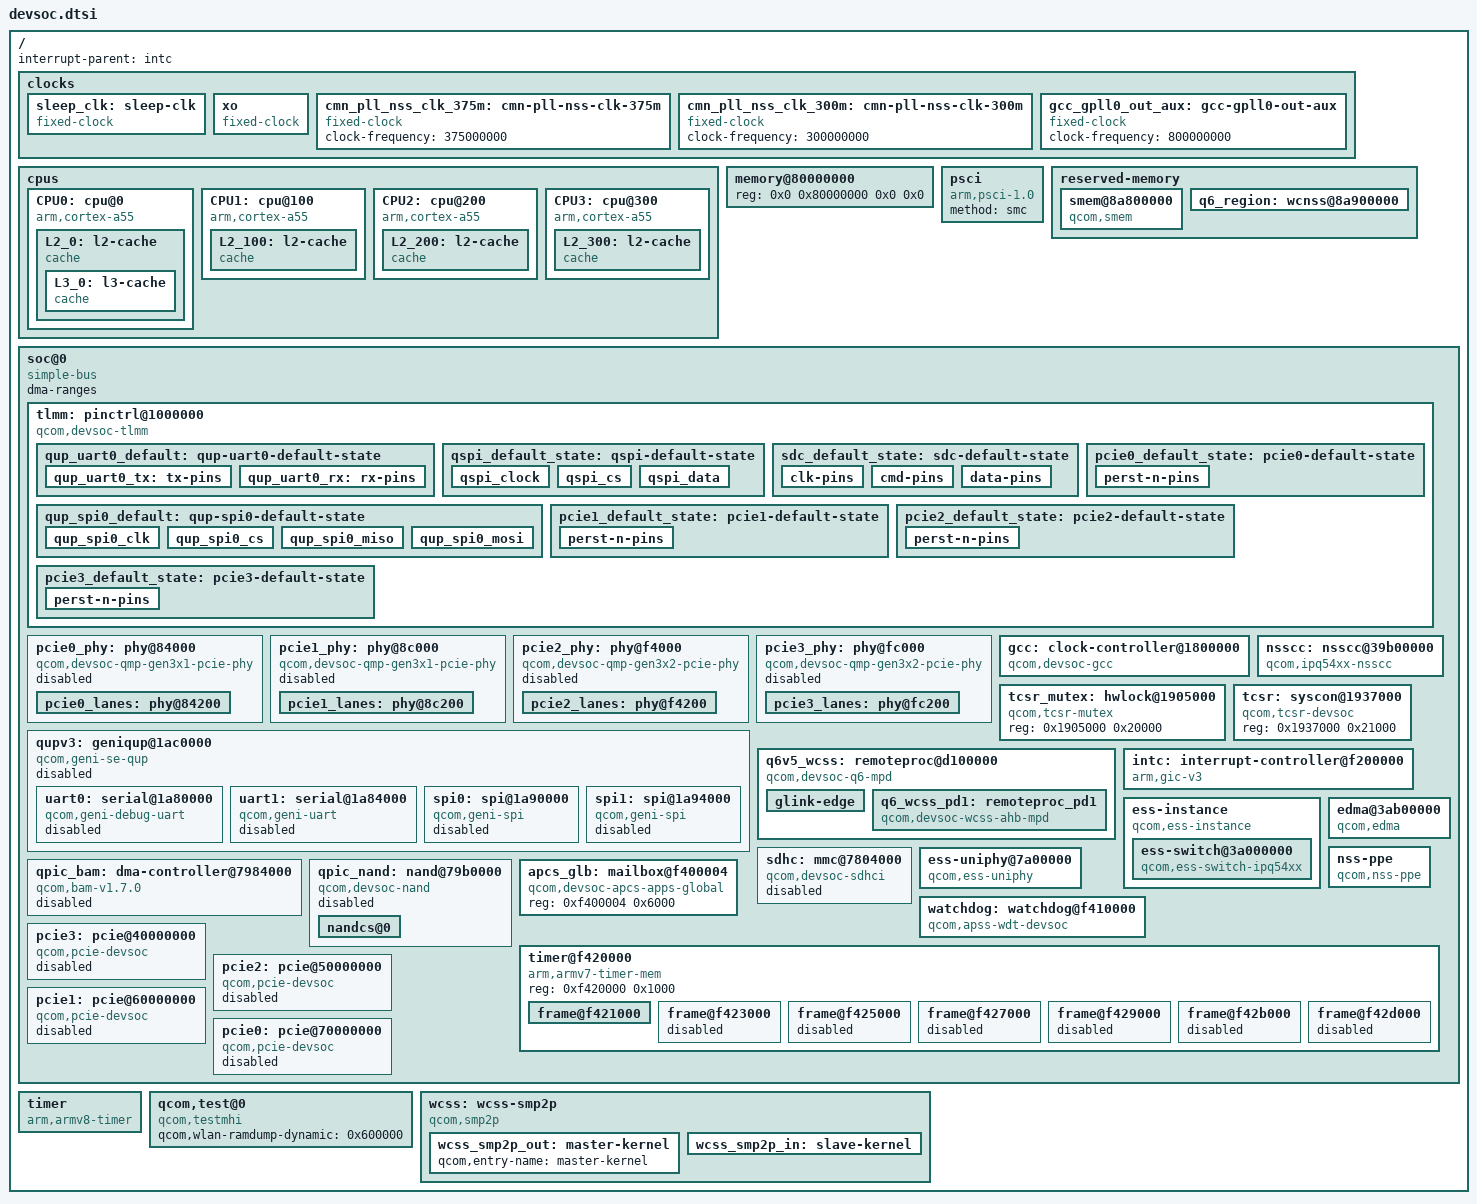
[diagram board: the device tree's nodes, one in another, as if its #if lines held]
// SPDX-License-Identifier: (GPL-2.0+ OR BSD-3-Clause)
/*
 * Dev SoC device tree source
 *
 * Copyright (c) 2020-2021 The Linux Foundation. All rights reserved.
 * Copyright (c) 2022-2023 Qualcomm Innovation Center, Inc. All rights reserved.
 */

#include <dt-bindings/interrupt-controller/arm-gic.h>
#include <dt-bindings/clock/qcom,devsoc-gcc.h>
#include <dt-bindings/reset/qcom,devsoc-gcc.h>
#include <dt-bindings/gpio/gpio.h>
#include <dt-bindings/clock/qcom,devsoc-nsscc.h>
#include <dt-bindings/reset/qcom,devsoc-nsscc.h>

/ {
	#address-cells = <2>;
	#size-cells = <2>;
	interrupt-parent = <&intc>;

	clocks {
		sleep_clk: sleep-clk {
			compatible = "fixed-clock";
			#clock-cells = <0>;
		};

		xo: xo {
			compatible = "fixed-clock";
			#clock-cells = <0>;
		};

		cmn_pll_nss_clk_375m: cmn-pll-nss-clk-375m {
			compatible = "fixed-clock";
			clock-frequency = <375000000>;
			#clock-cells = <0>;
		};

		cmn_pll_nss_clk_300m: cmn-pll-nss-clk-300m {
			compatible = "fixed-clock";
			clock-frequency = <300000000>;
			#clock-cells = <0>;
		};

		gcc_gpll0_out_aux: gcc-gpll0-out-aux {
			compatible = "fixed-clock";
			clock-frequency = <800000000>;
			#clock-cells = <0>;
		};
	};

	cpus: cpus {
		#address-cells = <1>;
		#size-cells = <0>;

		CPU0: cpu@0 {
			device_type = "cpu";
			compatible = "arm,cortex-a55";
			reg = <0x0>;
			enable-method = "psci";
			next-level-cache = <&L2_0>;
			L2_0: l2-cache {
				compatible = "cache";
				cache-level = <2>;
				cache-unified;
				next-level-cache = <&L3_0>;
				L3_0: l3-cache {
					compatible = "cache";
					cache-level = <3>;
					cache-unified;
				};
			};
		};

		CPU1: cpu@100 {
			device_type = "cpu";
			compatible = "arm,cortex-a55";
			enable-method = "psci";
			reg = <0x100>;
			next-level-cache = <&L2_100>;
			L2_100: l2-cache {
				compatible = "cache";
				cache-level = <2>;
				cache-unified;
				next-level-cache = <&L3_0>;
			};
		};

		CPU2: cpu@200 {
			device_type = "cpu";
			compatible = "arm,cortex-a55";
			enable-method = "psci";
			reg = <0x200>;
			next-level-cache = <&L2_200>;
			L2_200: l2-cache {
				compatible = "cache";
				cache-level = <2>;
				cache-unified;
				next-level-cache = <&L3_0>;
			};
		};

		CPU3: cpu@300 {
			device_type = "cpu";
			compatible = "arm,cortex-a55";
			enable-method = "psci";
			reg = <0x300>;
			next-level-cache = <&L2_300>;
			L2_300: l2-cache {
				compatible = "cache";
				cache-level = <2>;
				cache-unified;
				next-level-cache = <&L3_0>;
			};
		};
	};

	memory@80000000 {
		device_type = "memory";
		/* We expect the bootloader to fill in the size */
		reg = <0x0 0x80000000 0x0 0x0>;
	};

	psci {
		compatible = "arm,psci-1.0";
		method = "smc";
	};

	reserved-memory {
		#address-cells = <2>;
		#size-cells = <2>;
		ranges;

		smem@8a800000 {
			compatible = "qcom,smem";
			reg = <0x0 0x8a800000 0x0 0x100000>;
			no-map;

			hwlocks = <&tcsr_mutex 3>;
		};

		q6_region: wcnss@8a900000 {
			reg = <0x0 0x8a900000 0x0 0x02300000>;
			no-map;
		};
	};

	soc@0 {
		compatible = "simple-bus";
		#address-cells = <1>;
		#size-cells = <1>;
		ranges = <0 0 0 0xffffffff>;
		dma-ranges;

		tlmm: pinctrl@1000000 {
			compatible = "qcom,devsoc-tlmm";
			reg = <0x01000000 0x300000>;
			interrupts = <GIC_SPI 84 IRQ_TYPE_LEVEL_HIGH>;
			gpio-controller;
			#gpio-cells = <2>;
			gpio-ranges = <&tlmm 0 0 49>;
			interrupt-controller;
			#interrupt-cells = <2>;

			qup_uart0_default: qup-uart0-default-state {
				qup_uart0_tx: tx-pins {
					pins = "gpio13";
					function = "uart0_tx";
					drive-strength = <8>;
					bias-disable;
				};

				qup_uart0_rx: rx-pins {
					pins = "gpio12";
					function = "uart0_rx";
					drive-strength = <8>;
					bias-disable;
				};
			};

			qspi_default_state: qspi-default-state {
				qspi_clock {
					pins = "gpio5";
					function = "qspi_clk";
					drive-strength = <8>;
					bias-pull-down;
				};

				qspi_cs {
					pins = "gpio4";
					function = "qspi_cs";
					drive-strength = <8>;
					bias-pull-up;
				};

				qspi_data {
					pins = "gpio0", "gpio1", "gpio2", "gpio3";
					function = "qspi_data";
					drive-strength = <8>;
					bias-pull-down;
				};
			};

			sdc_default_state: sdc-default-state {
				clk-pins {
					pins = "gpio5";
					function = "sdc_clk";
					drive-strength = <8>;
					bias-disable;
				};

				cmd-pins {
					pins = "gpio4";
					function = "sdc_cmd";
					drive-strength = <8>;
					bias-pull-up;
				};

				data-pins {
					pins = "gpio0", "gpio1", "gpio2", "gpio3";
					function = "sdc_data";
					drive-strength = <8>;
					bias-pull-up;
				};
			};

			qup_spi0_default: qup-spi0-default-state {
				qup_spi0_clk {
					pins = "gpio6";
					function = "spi0_clk";
					drive-strength = <8>;
					bias-disable;
				};

				qup_spi0_cs {
					pins = "gpio7";
					function = "spi0_cs";
					drive-strength = <8>;
					bias-disable;
				};

				qup_spi0_miso {
					pins = "gpio8";
					function = "spi0_miso";
					drive-strength = <8>;
					bias-disable;
				};

				qup_spi0_mosi {
					pins = "gpio9";
					function = "spi0_mosi";
					drive-strength = <8>;
					bias-disable;
				};
			};

			pcie0_default_state: pcie0-default-state {
				perst-n-pins {
					pins = "gpio39";
					function = "gpio";
					drive-strength = <2>;
					bias-pull-down;
					output-low;
				};
			};

			pcie1_default_state: pcie1-default-state {
				perst-n-pins {
					pins = "gpio40";
					function = "gpio";
					drive-strength = <2>;
					bias-pull-down;
					output-low;
				};
			};

			pcie2_default_state: pcie2-default-state {
				perst-n-pins {
					pins = "gpio41";
					function = "gpio";
					drive-strength = <2>;
					bias-pull-down;
					output-low;
				};
			};

			pcie3_default_state: pcie3-default-state {
				perst-n-pins {
					pins = "gpio42";
					function = "gpio";
					drive-strength = <2>;
					bias-pull-down;
					output-low;
				};
			};
		};

		pcie0_phy: phy@84000 {
			compatible = "qcom,devsoc-qmp-gen3x1-pcie-phy";
			reg = <0x00084000 0x1bc>; /* Serdes PLL */
			#address-cells = <1>;
			#size-cells = <1>;
			ranges;

			clocks = <&gcc GCC_PCIE0_AUX_CLK>,
				 <&gcc GCC_PCIE0_AHB_CLK>,
				 <&gcc GCC_ANOC_PCIE0_1LANE_M_CLK>,
				 <&gcc GCC_CNOC_PCIE0_1LANE_S_CLK>;
			clock-names = "aux", "cfg_ahb", "anoc_lane", "snoc_lane";

			assigned-clocks = <&gcc GCC_PCIE0_AUX_CLK>,
					  <&gcc GCC_PCIE0_AHB_CLK>,
					  <&gcc GCC_ANOC_PCIE0_1LANE_M_CLK>,
					  <&gcc GCC_CNOC_PCIE0_1LANE_S_CLK>;
			assigned-clock-rates = <20000000>,
					       <100000000>,
					       <240000000>,
					       <240000000>;

			resets = <&gcc GCC_PCIE0_PHY_BCR>,
				 <&gcc GCC_PCIE0PHY_PHY_BCR>;
			reset-names = "phy", "common";

			status = "disabled";

			pcie0_lanes: phy@84200 {
				reg = <0x00084200 0x16c>, /* Serdes Tx0 */
				      <0x00084400 0x200>, /* Serdes Rx0 */
				      <0x00084800 0x1f0>, /* PCS: Lane0, COM, PCIE */
				      <0x00084c00 0x0f4>; /* pcs_misc */

				#phy-cells = <0>;

				clocks = <&gcc GCC_PCIE0_PIPE_CLK>;
				clock-names = "pipe0";
				clock-output-names = "gcc_pcie0_pipe_clk_src";
				#clock-cells = <0>;
			};
		};

		pcie1_phy: phy@8c000 {
			compatible = "qcom,devsoc-qmp-gen3x1-pcie-phy";
			reg = <0x0008c000 0x1bc>; /* Serdes PLL */
			#address-cells = <1>;
			#size-cells = <1>;
			ranges;

			clocks = <&gcc GCC_PCIE1_AUX_CLK>,
				 <&gcc GCC_PCIE1_AHB_CLK>,
				 <&gcc GCC_ANOC_PCIE1_1LANE_M_CLK>,
				 <&gcc GCC_CNOC_PCIE1_1LANE_S_CLK>;
			clock-names = "aux", "cfg_ahb", "anoc_lane", "snoc_lane";

			assigned-clocks = <&gcc GCC_PCIE1_AUX_CLK>,
					  <&gcc GCC_PCIE1_AHB_CLK>,
					  <&gcc GCC_ANOC_PCIE1_1LANE_M_CLK>,
					  <&gcc GCC_CNOC_PCIE1_1LANE_S_CLK>;
			assigned-clock-rates = <20000000>,
					       <100000000>,
					       <240000000>,
					       <240000000>;

			resets = <&gcc GCC_PCIE1_PHY_BCR>,
				 <&gcc GCC_PCIE1PHY_PHY_BCR>;
			reset-names = "phy", "common";

			status = "disabled";

			pcie1_lanes: phy@8c200 {
				reg = <0x0008c200 0x16c>, /* Serdes Tx0 */
				      <0x0008c400 0x200>, /* Serdes Rx0 */
				      <0x0008c800 0x1f0>, /* PCS: Lane0, COM, PCIE */
				      <0x0008cc00 0x0f4>; /* pcs_misc */

				#phy-cells = <0>;

				clocks = <&gcc GCC_PCIE1_PIPE_CLK>;
				clock-names = "pipe0";
				clock-output-names = "gcc_pcie1_pipe_clk_src";
				#clock-cells = <0>;
			};
		};

		pcie2_phy: phy@f4000 {
			compatible = "qcom,devsoc-qmp-gen3x2-pcie-phy";
			reg = <0x000f4000 0x1bc>; /* Serdes PLL */
			#address-cells = <1>;
			#size-cells = <1>;
			ranges;

			clocks = <&gcc GCC_PCIE2_AUX_CLK>,
				 <&gcc GCC_PCIE2_AHB_CLK>,
				 <&gcc GCC_ANOC_PCIE2_2LANE_M_CLK>,
				 <&gcc GCC_CNOC_PCIE2_2LANE_S_CLK>;
			clock-names = "aux", "cfg_ahb", "anoc_lane", "snoc_lane";

			assigned-clocks = <&gcc GCC_PCIE2_AUX_CLK>,
					  <&gcc GCC_PCIE2_AHB_CLK>,
					  <&gcc GCC_ANOC_PCIE2_2LANE_M_CLK>,
					  <&gcc GCC_CNOC_PCIE2_2LANE_S_CLK>;
			assigned-clock-rates = <20000000>,
					       <100000000>,
					       <266666666>,
					       <240000000>;

			resets = <&gcc GCC_PCIE2_PHY_BCR>,
				 <&gcc GCC_PCIE2PHY_PHY_BCR>;
			reset-names = "phy", "common";

			status = "disabled";

			pcie2_lanes: phy@f4200 {
				reg = <0x000f4200 0x16c>, /* Serdes Tx0 */
				      <0x000f4400 0x200>, /* Serdes Rx0 */
				      <0x000f5000 0x1f0>, /* PCS: Lane0, COM, PCIE */
				      <0x000f4600 0x16c>, /* Serdes Tx1 */
				      <0x000f4800 0x200>, /* Serdes Rx1 */
				      <0x000f5400 0x0f8>; /* pcs_misc */

				#phy-cells = <0>;

				clocks = <&gcc GCC_PCIE2_PIPE_CLK>;
				clock-names = "pipe0";
				clock-output-names = "gcc_pcie2_pipe_clk_src";
				#clock-cells = <0>;
			};
		};

		pcie3_phy: phy@fc000 {
			compatible = "qcom,devsoc-qmp-gen3x2-pcie-phy";
			reg = <0x000fc000 0x1bc>; /* Serdes PLL */
			#address-cells = <1>;
			#size-cells = <1>;
			ranges;

			clocks = <&gcc GCC_PCIE3_AUX_CLK>,
				 <&gcc GCC_PCIE3_AHB_CLK>,
				 <&gcc GCC_ANOC_PCIE3_2LANE_M_CLK>,
				 <&gcc GCC_CNOC_PCIE3_2LANE_S_CLK>;
			clock-names = "aux", "cfg_ahb", "anoc_lane", "snoc_lane";

			assigned-clocks = <&gcc GCC_PCIE3_AUX_CLK>,
					  <&gcc GCC_PCIE3_AHB_CLK>,
					  <&gcc GCC_ANOC_PCIE3_2LANE_M_CLK>,
					  <&gcc GCC_CNOC_PCIE3_2LANE_S_CLK>;
			assigned-clock-rates = <20000000>,
					       <100000000>,
					       <266666666>,
					       <240000000>;

			resets = <&gcc GCC_PCIE3_PHY_BCR>,
				 <&gcc GCC_PCIE3PHY_PHY_BCR>;
			reset-names = "phy", "common";

			status = "disabled";

			pcie3_lanes: phy@fc200 {
				reg = <0x000fc200 0x16c>, /* Serdes Tx0 */
				      <0x000fc400 0x200>, /* Serdes Rx0 */
				      <0x000fd000 0x1f0>, /* PCS: Lane0, COM, PCIE */
				      <0x000fc600 0x16c>, /* Serdes Tx1 */
				      <0x000fc800 0x200>, /* Serdes Rx1 */
				      <0x000fd400 0x0f8>; /* pcs_misc */

				#phy-cells = <0>;

				clocks = <&gcc GCC_PCIE3_PIPE_CLK>;
				clock-names = "pipe0";
				clock-output-names = "gcc_pcie3_pipe_clk_src";
				#clock-cells = <0>;
			};
		};

		gcc: clock-controller@1800000 {
			compatible = "qcom,devsoc-gcc";
			reg = <0x01800000 0x40000>;
			clocks = <&xo>,
				 <&sleep_clk>;
			#clock-cells = <1>;
			#reset-cells = <1>;
			#power-domain-cells = <1>;
                };

		nsscc: nsscc@39b00000{
			compatible = "qcom,ipq54xx-nsscc";
			reg = <0x39b00000 0x80000>;
			clocks = <&xo>,
				<&cmn_pll_nss_clk_375m>,
				<&cmn_pll_nss_clk_300m>,
				<&gcc_gpll0_out_aux>;
			clock-names = "xo",
					"cmn_pll_nss_clk_375m",
					"cmn_pll_nss_clk_300m",
					"gcc_gpll0_out_aux";
			#clock-cells = <0x1>;
			#reset-cells = <0x1>;
		};

		tcsr_mutex: hwlock@1905000 {
			compatible = "qcom,tcsr-mutex";
			reg = <0x1905000 0x20000>;
			#hwlock-cells = <1>;
		};

		tcsr: syscon@1937000 {
			compatible = "qcom,tcsr-devsoc", "syscon";
			reg = <0x1937000 0x21000>;
		};

		qupv3: geniqup@1ac0000 {
			compatible = "qcom,geni-se-qup";
			reg = <0x01ac0000 0x2000>;
			clocks = <&gcc GCC_QUPV3_AHB_MST_CLK>,
				 <&gcc GCC_QUPV3_AHB_SLV_CLK>;
			clock-names = "m-ahb", "s-ahb";
			ranges;

			status = "disabled";

			uart0: serial@1a80000 {
				compatible = "qcom,geni-debug-uart";
				reg = <0x01a80000 0x4000>;
				clocks = <&gcc GCC_QUPV3_UART0_CLK>;
				clock-names = "se";
				interrupts = <GIC_SPI 339 IRQ_TYPE_LEVEL_HIGH>;
				status = "disabled";
			};

			uart1: serial@1a84000 {
				compatible = "qcom,geni-uart";
				reg = <0x01a84000 0x4000>;
				clocks = <&gcc GCC_QUPV3_UART1_CLK>;
				clock-names = "se";
				interrupts = <GIC_SPI 340 IRQ_TYPE_LEVEL_HIGH>;
				status = "disabled";
			};

			spi0: spi@1a90000 {
				compatible = "qcom,geni-spi";
				reg = <0x1a90000 0x4000>;
				clocks = <&gcc GCC_QUPV3_SPI0_CLK>;
				clock-names = "se";
				interrupts = <GIC_SPI 343 IRQ_TYPE_LEVEL_HIGH>;
				status = "disabled";
			};

			spi1: spi@1a94000 {
				compatible = "qcom,geni-spi";
				reg = <0x1a94000 0x4000>;
				clocks = <&gcc GCC_QUPV3_SPI1_CLK>;
				clock-names = "se";
				interrupts = <GIC_SPI 344 IRQ_TYPE_LEVEL_HIGH>;
				status = "disabled";
			};
		};

		q6v5_wcss: remoteproc@d100000 {
			compatible = "qcom,devsoc-q6-mpd";
			#address-cells = <1>;
			#size-cells = <1>;
			ranges;
#ifdef __QCOM_NON_SECURE_PIL__
			reg = <0xd100000 0x4040>;
			reg-names = "qdsp6";
			resets = <&gcc GCC_WCSS_Q6_BCR>;
			reset-names = "wcss_q6_reset";
			clocks = <&gcc GCC_Q6_TSCTR_1TO2_CLK>,
				 <&gcc GCC_Q6SS_TRIG_CLK>,
				 <&gcc GCC_Q6_AHB_S_CLK>,
				 <&gcc GCC_Q6_AHB_CLK>,
				 <&gcc GCC_Q6SS_ATBM_CLK>,
				 <&gcc GCC_Q6_AXIM_CLK>,
				 <&gcc GCC_Q6SS_BOOT_CLK>,
				 <&gcc GCC_Q6SS_PCLKDBG_CLK>,
				 <&gcc GCC_WCSS_ECAHB_CLK>,
				 <&gcc GCC_CNOC_WCSS_AHB_CLK>;

			clock-names = "q6_tsctr_1to2",
				      "q6ss_trig",
				      "q6_ahb_s",
				      "q6_ahb",
				      "q6ss_atbm",
				      "q6_axim",
				      "q6ss_boot",
				      "q6ss_pclkdbg",
				      "wcss_ecahb",
				      "cnoc_wcss_ahb";
			qcom,q6-tcsr-regs = <&tcsr 0x6204 0x1B000>;
#endif
			firmware = "devsoc/q6_fw0.mdt";
			interrupts-extended = <&intc GIC_SPI 508 IRQ_TYPE_EDGE_RISING>,
					      <&wcss_smp2p_in 0 0>,
					      <&wcss_smp2p_in 1 0>,
					      <&wcss_smp2p_in 2 0>,
					      <&wcss_smp2p_in 3 0>;
			interrupt-names = "wdog",
					  "fatal",
					  "ready",
					  "handover",
					  "stop-ack";
			qcom,smem-states = <&wcss_smp2p_out 0>,
					   <&wcss_smp2p_out 1>;
			qcom,smem-state-names = "shutdown",
						"stop";

			memory-region = <&q6_region>;
			qcom,bootargs_smem = <507>;
			qcom,bootargs_version = <2>;
			qcom,userpd-bootargs;

			glink-edge {
				interrupts = <GIC_SPI 500 IRQ_TYPE_EDGE_RISING>;
				label = "rtr";
				qcom,remote-pid = <1>;
				mboxes = <&apcs_glb 8>;
			};

			q6_wcss_pd1: remoteproc_pd1 {
				compatible = "qcom,devsoc-wcss-ahb-mpd";
				firmware = "devsoc/q6_fw1.mdt";
				m3_firmware = "devsoc/iu_fw.mdt";
				interrupts-extended = <&wcss_smp2p_in 8 0>,
						      <&wcss_smp2p_in 9 0>,
						      <&wcss_smp2p_in 12 0>,
						      <&wcss_smp2p_in 11 0>;
				interrupt-names = "fatal",
						  "ready",
						  "spawn-ack",
						  "stop-ack";

				qcom,smem-states = <&wcss_smp2p_out 8>,
						   <&wcss_smp2p_out 9>,
						   <&wcss_smp2p_out 10>;
				qcom,smem-state-names = "shutdown",
							"stop",
							"spawn";
			};
		};

		intc: interrupt-controller@f200000 {
			compatible = "arm,gic-v3";
			reg = <0xf200000 0x10000>, /* GICD */
			      <0xf240000 0x80000>; /* GICR * 4 regions */
			#interrupt-cells = <0x3>;
			interrupt-controller;
			#redistributor-regions = <1>;
			redistributor-stride = <0x0 0x20000>;
			interrupts = <GIC_PPI 9 IRQ_TYPE_LEVEL_HIGH>;
			mbi-ranges = <672 128>;
			msi-controller;
		};

		ess-instance {
			compatible = "qcom,ess-instance";
			ess-switch@3a000000 {
				compatible = "qcom,ess-switch-ipq54xx";
				switch_access_mode = "local bus";
				reg = <0x3a000000 0x1000000>;
				clocks = <&gcc GCC_CMN_12GPLL_AHB_CLK>,
					<&gcc GCC_CMN_12GPLL_SYS_CLK>,
					<&gcc GCC_UNIPHY0_AHB_CLK>,
					<&gcc GCC_UNIPHY0_SYS_CLK>,
					<&gcc GCC_UNIPHY1_AHB_CLK>,
					<&gcc GCC_UNIPHY1_SYS_CLK>,
					<&gcc GCC_UNIPHY2_AHB_CLK>,
					<&gcc GCC_UNIPHY2_SYS_CLK>,
					<&gcc GCC_NSSNOC_NSSCC_CLK>,
					<&gcc GCC_NSSCC_CLK>,
					<&gcc GCC_NSSNOC_SNOC_1_CLK>,
					<&gcc GCC_NSSNOC_SNOC_CLK>,
			//		<&gcc GCC_IM_SLEEP_CLK>,
					<&nsscc NSS_CC_PORT1_MAC_CLK>,
					<&nsscc NSS_CC_PORT2_MAC_CLK>,
					<&nsscc NSS_CC_PORT3_MAC_CLK>,
					<&nsscc NSS_CC_PPE_SWITCH_CLK>,
					<&nsscc NSS_CC_PPE_SWITCH_CFG_CLK>,
					<&nsscc NSS_CC_NSSNOC_PPE_CLK>,
					<&nsscc NSS_CC_NSSNOC_PPE_CFG_CLK>,
					<&nsscc NSS_CC_PPE_EDMA_CLK>,
					<&nsscc NSS_CC_PPE_EDMA_CFG_CLK>,
					<&nsscc NSS_CC_PPE_SWITCH_IPE_CLK>,
					<&nsscc NSS_CC_PPE_SWITCH_BTQ_CLK>,
					<&nsscc NSS_CC_PORT1_RX_CLK>,
					<&nsscc NSS_CC_PORT1_TX_CLK>,
					<&nsscc NSS_CC_PORT2_RX_CLK>,
					<&nsscc NSS_CC_PORT2_TX_CLK>,
					<&nsscc NSS_CC_PORT3_RX_CLK>,
					<&nsscc NSS_CC_PORT3_TX_CLK>,
					<&nsscc NSS_CC_UNIPHY_PORT1_RX_CLK>,
					<&nsscc NSS_CC_UNIPHY_PORT1_TX_CLK>,
					<&nsscc NSS_CC_UNIPHY_PORT2_RX_CLK>,
					<&nsscc NSS_CC_UNIPHY_PORT2_TX_CLK>,
					<&nsscc NSS_CC_UNIPHY_PORT3_RX_CLK>,
					<&nsscc NSS_CC_UNIPHY_PORT3_TX_CLK>;
				clock-names = "cmn_ahb_clk",
					"cmn_sys_clk",
					"uniphy0_ahb_clk",
					"uniphy0_sys_clk",
					"uniphy1_ahb_clk",
					"uniphy1_sys_clk",
					"uniphy2_ahb_clk",
					"uniphy2_sys_clk",
					"gcc_nssnoc_nsscc_clk",
					"gcc_nsscc_clk",
					"gcc_nssnoc_snoc_1_clk",
					"gcc_nssnoc_snoc_clk",
			//		"gcc_im_sleep_clk",
					"port1_mac_clk",
					"port2_mac_clk",
					"port3_mac_clk",
					"nss_ppe_clk",
					"nss_ppe_cfg_clk",
					"nssnoc_ppe_clk",
					"nssnoc_ppe_cfg_clk",
					"nss_edma_clk",
					"nss_edma_cfg_clk",
					"nss_ppe_ipe_clk",
					"nss_ppe_btq_clk",
					"nss_port1_rx_clk",
					"nss_port1_tx_clk",
					"nss_port2_rx_clk",
					"nss_port2_tx_clk",
					"nss_port3_rx_clk",
					"nss_port3_tx_clk",
					"uniphy0_port1_rx_clk",
					"uniphy0_port1_tx_clk",
					"uniphy1_port5_rx_clk",
					"uniphy1_port5_tx_clk",
					"uniphy2_port6_rx_clk",
					"uniphy2_port6_tx_clk";
				resets = <&nsscc NSS_CC_PPE_BCR>,
					<&gcc GCC_UNIPHY0_BCR>,
					<&gcc GCC_UNIPHY1_BCR>,
					<&gcc GCC_UNIPHY2_BCR>,
/*
					<&gcc GCC_UNIPHY0_AHB_CLK_ARES>,
					<&gcc GCC_UNIPHY1_AHB_CLK_ARES>,
					<&gcc GCC_UNIPHY2_AHB_CLK_ARES>,
					<&gcc GCC_UNIPHY0_SYS_CLK_ARES>,
					<&gcc GCC_UNIPHY1_SYS_CLK_ARES>,
					<&gcc GCC_UNIPHY2_SYS_CLK_ARES>,
					<&gcc GCC_UNIPHY0_XPCS_ARES>,
					<&gcc GCC_UNIPHY1_XPCS_ARES>,
					<&gcc GCC_UNIPHY2_XPCS_ARES>,
*/
					<&nsscc NSS_CC_UNIPHY_PORT1_RX_CLK_ARES>,
					<&nsscc NSS_CC_UNIPHY_PORT1_TX_CLK_ARES>,
					<&nsscc NSS_CC_UNIPHY_PORT2_RX_CLK_ARES>,
					<&nsscc NSS_CC_UNIPHY_PORT2_TX_CLK_ARES>,
					<&nsscc NSS_CC_UNIPHY_PORT3_RX_CLK_ARES>,
					<&nsscc NSS_CC_UNIPHY_PORT3_TX_CLK_ARES>,
					<&nsscc NSS_CC_PORT1_RX_CLK_ARES>,
					<&nsscc NSS_CC_PORT1_TX_CLK_ARES>,
					<&nsscc NSS_CC_PORT2_RX_CLK_ARES>,
					<&nsscc NSS_CC_PORT2_TX_CLK_ARES>,
					<&nsscc NSS_CC_PORT3_RX_CLK_ARES>,
					<&nsscc NSS_CC_PORT3_TX_CLK_ARES>,
					<&nsscc NSS_CC_PORT1_MAC_CLK_ARES>,
					<&nsscc NSS_CC_PORT2_MAC_CLK_ARES>,
					<&nsscc NSS_CC_PORT3_MAC_CLK_ARES>;
				reset-names = "ppe_rst",
					"uniphy0_soft_rst",
					"uniphy1_soft_rst",
					"uniphy2_soft_rst",
/*
					"uniphy0_ahb_rst",
					"uniphy1_ahb_rst",
					"uniphy2_ahb_rst",
					"uniphy0_sys_rst",
					"uniphy1_sys_rst",
					"uniphy2_sys_rst",
					"uniphy0_xpcs_rst",
					"uniphy1_xpcs_rst",
					"uniphy2_xpcs_rst",
*/
					"uniphy_port1_rx_rst",
					"uniphy_port1_tx_rst",
					"uniphy_port2_rx_rst",
					"uniphy_port2_tx_rst",
					"uniphy_port3_rx_rst",
					"uniphy_port3_tx_rst",
					"nss_port1_rx_rst",
					"nss_port1_tx_rst",
					"nss_port2_rx_rst",
					"nss_port2_tx_rst",
					"nss_port3_rx_rst",
					"nss_port3_tx_rst",
					"nss_port1_mac_rst",
					"nss_port2_mac_rst",
					"nss_port3_mac_rst";

			};
		};

		sdhc: mmc@7804000 {
			compatible = "qcom,devsoc-sdhci", "qcom,sdhci-msm-v5";
			reg = <0x07804000 0x1000>, <0x07805000 0x1000>;

			interrupts = <GIC_SPI 116 IRQ_TYPE_LEVEL_HIGH>,
				     <GIC_SPI 119 IRQ_TYPE_LEVEL_HIGH>;
			interrupt-names = "hc_irq", "pwr_irq";

			clocks = <&gcc GCC_SDCC1_AHB_CLK>,
				 <&gcc GCC_SDCC1_APPS_CLK>,
				 <&xo>;
			clock-names = "iface", "core", "xo";

			pinctrl-0 = <&sdc_default_state>;
			pinctrl-names = "default";

			status = "disabled";
		};

		qpic_bam: dma-controller@7984000 {
			compatible = "qcom,bam-v1.7.0";
			reg = <0x7984000 0x1c000>;
			interrupts = <GIC_SPI 109 IRQ_TYPE_LEVEL_HIGH>;
			clocks = <&gcc GCC_QPIC_AHB_CLK>;
			clock-names = "bam_clk";
			#dma-cells = <1>;
			qcom,ee = <0>;
			status = "disabled";
		};

		qpic_nand: nand@79b0000 {
			compatible = "qcom,devsoc-nand";
			reg = <0x79b0000 0x10000>;
			#address-cells = <1>;
			#size-cells = <0>;
			clocks = <&gcc GCC_QPIC_CLK>,
				 <&gcc GCC_QPIC_AHB_CLK>,
				 <&gcc GCC_QPIC_IO_MACRO_CLK>;
			clock-names = "core", "aon", "io_macro";

			dmas = <&qpic_bam 0>,
			       <&qpic_bam 1>,
			       <&qpic_bam 2>,
			       <&qpic_bam 3>;
			dma-names = "tx", "rx", "cmd", "sts";

			qcom,io_macro_max_clk = <320000000>;
			qcom,io_macro_clk_rates = <24000000 100000000 200000000 \
						   320000000>;

			pinctrl-0 = <&qspi_default_state>;
			pinctrl-names = "default";

			status = "disabled";
			nandcs@0 {
				reg = <0>;
				#address-cells = <1>;
				#size-cells = <1>;

				nand-ecc-strength = <8>;
				nand-ecc-step-size = <512>;
				nand-bus-width = <8>;
			};
		};

		ess-uniphy@7a00000 {
			compatible = "qcom,ess-uniphy";
			reg = <0x7a00000 0x30000>;
			uniphy_access_mode = "local bus";
		};

		edma@3ab00000 {
			compatible = "qcom,edma";
			reg = <0x3ab00000 0xef800>;
			reg-names = "edma-reg-base";
			reset-names = "edma_rst";
			clocks = <&nsscc NSS_CC_NSS_CSR_CLK>,
				<&nsscc NSS_CC_NSSNOC_NSS_CSR_CLK>,
				<&nsscc NSS_CC_CE_APB_CLK>,
				<&nsscc NSS_CC_CE_AXI_CLK>,
				<&nsscc NSS_CC_NSSNOC_CE_APB_CLK>,
				<&nsscc NSS_CC_NSSNOC_CE_AXI_CLK>,
				<&gcc GCC_NSS_TS_CLK>,
				<&gcc GCC_NSSCC_CLK>,
				<&gcc GCC_NSSCFG_CLK>,
				<&gcc GCC_NSSNOC_ATB_CLK>,
				<&gcc GCC_NSSNOC_NSSCC_CLK>,
				<&gcc GCC_NSSNOC_MEMNOC_CLK>,
				<&gcc GCC_NSSNOC_MEM_NOC_1_CLK>,
				<&gcc GCC_NSSNOC_PCNOC_1_CLK>,
				<&gcc GCC_NSSNOC_QOSGEN_REF_CLK>,
				<&gcc GCC_NSSNOC_SNOC_1_CLK>,
				<&gcc GCC_NSSNOC_SNOC_CLK>,
				<&gcc GCC_NSSNOC_TIMEOUT_REF_CLK>,
				<&gcc GCC_NSSNOC_XO_DCD_CLK>,
				<&gcc GCC_GEMNOC_NSSNOC_CLK>;
			clock-names = "nss-csr-clk", "nss-nssnoc-csr-clk", "nss-ce-apb-clk",
				"nss-ce-axi-clk", "nss-nssnoc-ce-apb-clk", "nss-nssnoc-ce-axi-clk",
				"nss-ts-clk", "nss-nsscc-clk", "nss-nsscfg-clk", "nss-nssnoc-atb-clk",
				"nss-nssnoc-nsscc-clk", "nss-nssnoc-memnoc-clk", "nss-nssnoc-mem-noc-1-clk",
				"nss-nssnoc-pcnoc-1-clk", "nss-nssnoc-qosgen-ref-clk", "nss-nssnoc-snoc-1-clk",
				"nss-nssnoc-snoc-clk", "nss-nssnoc-timeout-ref-clk", "nss-nssnoc-xo-dcd-clk",
				"nss-gemnoc-nssnoc-clk";
                };

		nss-ppe {
			compatible = "qcom,nss-ppe";
		};

		apcs_glb: mailbox@f400004 {
			compatible = "qcom,devsoc-apcs-apps-global",
				     "qcom,ipq6018-apcs-apps-global";
			reg = <0xf400004 0x6000>;
			#clock-cells = <1>;
			#mbox-cells = <1>;
		};

		watchdog: watchdog@f410000 {
			compatible = "qcom,apss-wdt-devsoc", "qcom,kpss-wdt";
			reg = <0xf410000 0x1000>;
			interrupts = <GIC_SPI 0 IRQ_TYPE_EDGE_RISING>;
			clocks = <&sleep_clk>;
			timeout-sec = <30>;
		};

		timer@f420000 {
			compatible = "arm,armv7-timer-mem";
			reg = <0xf420000 0x1000>;
			#address-cells = <1>;
			#size-cells = <1>;
			ranges;

			frame@f421000 {
				reg = <0xf421000 0x1000>,
				      <0xf422000 0x1000>;
				interrupts = <GIC_SPI 8 IRQ_TYPE_LEVEL_HIGH>,
					     <GIC_SPI 6 IRQ_TYPE_LEVEL_HIGH>;
				frame-number = <0>;
			};

			frame@f423000 {
				reg = <0xf423000 0x1000>;
				interrupts = <GIC_SPI 9 IRQ_TYPE_LEVEL_HIGH>;
				frame-number = <1>;
				status = "disabled";
			};

			frame@f425000 {
				reg = <0xf425000 0x1000>,
				      <0xf426000 0x1000>;
				interrupts = <GIC_SPI 10 IRQ_TYPE_LEVEL_HIGH>;
				frame-number = <2>;
				status = "disabled";
			};

			frame@f427000 {
				reg = <0xf427000 0x1000>;
				interrupts = <GIC_SPI 11 IRQ_TYPE_LEVEL_HIGH>;
				frame-number = <3>;
				status = "disabled";
			};

			frame@f429000 {
				reg = <0xf429000 0x1000>;
				interrupts = <GIC_SPI 12 IRQ_TYPE_LEVEL_HIGH>;
				frame-number = <4>;
				status = "disabled";
			};

			frame@f42b000 {
				reg = <0xf42b000 0x1000>;
				interrupts = <GIC_SPI 13 IRQ_TYPE_LEVEL_HIGH>;
				frame-number = <5>;
				status = "disabled";
			};

			frame@f42d000 {
				reg = <0xf42d000 0x1000>;
				interrupts = <GIC_SPI 14 IRQ_TYPE_LEVEL_HIGH>;
				frame-number = <6>;
				status = "disabled";
			};
		};

		/* 2L controller */
		pcie3: pcie@40000000 {
			compatible = "qcom,pcie-devsoc";
			reg =  <0x40000000 0xf1d>,
			       <0x40000f20 0xa8>,
			       <0x40001000 0x1000>,
			       <0xf8000 0x3000>,
			       <0x40100000 0x1000>;
			reg-names = "dbi", "elbi", "atu", "parf", "config";
			device_type = "pci";
			linux,pci-domain = <3>;
			bus-range = <0x00 0xff>;
			num-lanes = <2>;
			#address-cells = <3>;
			#size-cells = <2>;

			ranges = <0x81000000 0 0x40200000 0x40200000 0 0x00100000>,   /* downstream I/O */
				 <0x82000000 0 0x40300000 0x40300000 0 0x0fd00000>; /* non-prefetchable memory */

			#interrupt-cells = <1>;
			interrupt-map-mask = <0 0 0 0x7>;
			interrupt-map = <0 0 0 1 &intc 0 479 IRQ_TYPE_LEVEL_HIGH>, /* int_a */
					<0 0 0 2 &intc 0 480 IRQ_TYPE_LEVEL_HIGH>, /* int_b */
					<0 0 0 3 &intc 0 481 IRQ_TYPE_LEVEL_HIGH>, /* int_c */
					<0 0 0 4 &intc 0 482 IRQ_TYPE_LEVEL_HIGH>; /* int_d */

			interrupts = <GIC_SPI 478 IRQ_TYPE_LEVEL_HIGH>;
			interrupt-names = "global_irq";

			clocks = <&gcc GCC_PCIE3_AXI_M_CLK>,
				 <&gcc GCC_PCIE3_AXI_S_CLK>,
				 <&gcc GCC_PCIE3_AHB_CLK>,
				 <&gcc GCC_PCIE3_AUX_CLK>,
				 <&gcc GCC_PCIE3_AXI_S_BRIDGE_CLK>,
				 <&gcc GCC_PCIE3_RCHNG_CLK>;

			clock-names = "axi_m",
				      "axi_s",
				      "ahb",
				      "aux",
				      "axi_bridge",
				      "rchng";

			assigned-clocks = <&gcc GCC_PCIE3_AUX_CLK>,
					<&gcc GCC_PCIE3_AXI_M_CLK>,
					<&gcc GCC_PCIE3_AXI_S_BRIDGE_CLK>,
					<&gcc GCC_PCIE3_AXI_S_CLK>,
					<&gcc GCC_PCIE3_RCHNG_CLK>;

			assigned-clock-rates = <20000000>,
						<266666666>,
						<240000000>,
						<240000000>,
						<100000000>;

			resets = <&gcc GCC_PCIE3_PIPE_ARES>,
				 <&gcc GCC_PCIE3_CORE_STICKY_RESET>,
				 <&gcc GCC_PCIE3_AXI_M_ARES>,
				 <&gcc GCC_PCIE3_AXI_S_ARES>,
				 <&gcc GCC_PCIE3_AXI_M_STICKY_RESET>,
				 <&gcc GCC_PCIE3_AXI_S_STICKY_RESET>,
				 <&gcc GCC_PCIE3_AHB_ARES>,
				 <&gcc GCC_PCIE3_AUX_ARES>;

			reset-names = "pipe",
				      "sticky",
				      "axi_m",
				      "axi_s",
				      "axi_m_sticky",
				      "axi_s_sticky",
				      "ahb",
				      "aux";

			msi-parent = <&intc>;

			pinctrl-0 = <&pcie3_default_state>;
			pinctrl-names = "default";

			phys = <&pcie3_lanes>;
			phy-names = "pciephy";

			perst-gpio = <&tlmm 42 GPIO_ACTIVE_LOW>;
			status = "disabled";
		};

		/* 2L controller */
		pcie2: pcie@50000000 {
			compatible = "qcom,pcie-devsoc";
			reg =  <0x50000000 0xf1d>,
			       <0x50000f20 0xa8>,
			       <0x50001000 0x1000>,
			       <0xf0000 0x3000>,
			       <0x50100000 0x1000>;
			reg-names = "dbi", "elbi", "atu", "parf", "config";
			device_type = "pci";
			linux,pci-domain = <2>;
			bus-range = <0x00 0xff>;
			num-lanes = <2>;
			#address-cells = <3>;
			#size-cells = <2>;

			ranges = <0x81000000 0 0x50200000 0x50200000 0 0x00100000>,   /* downstream I/O */
				 <0x82000000 0 0x50300000 0x50300000 0 0x0fd00000>; /* non-prefetchable memory */

			#interrupt-cells = <1>;
			interrupt-map-mask = <0 0 0 0x7>;
			interrupt-map = <0 0 0 1 &intc 0 464 IRQ_TYPE_LEVEL_HIGH>, /* int_a */
					<0 0 0 2 &intc 0 465 IRQ_TYPE_LEVEL_HIGH>, /* int_b */
					<0 0 0 3 &intc 0 466 IRQ_TYPE_LEVEL_HIGH>, /* int_c */
					<0 0 0 4 &intc 0 467 IRQ_TYPE_LEVEL_HIGH>; /* int_d */

			interrupts = <GIC_SPI 463 IRQ_TYPE_LEVEL_HIGH>;
			interrupt-names = "global_irq";

			clocks = <&gcc GCC_PCIE2_AXI_M_CLK>,
				 <&gcc GCC_PCIE2_AXI_S_CLK>,
				 <&gcc GCC_PCIE2_AHB_CLK>,
				 <&gcc GCC_PCIE2_AUX_CLK>,
				 <&gcc GCC_PCIE2_AXI_S_BRIDGE_CLK>,
				 <&gcc GCC_PCIE2_RCHNG_CLK>;

			clock-names = "axi_m",
				      "axi_s",
				      "ahb",
				      "aux",
				      "axi_bridge",
				      "rchng";

			assigned-clocks = <&gcc GCC_PCIE2_AUX_CLK>,
					<&gcc GCC_PCIE2_AXI_M_CLK>,
					<&gcc GCC_PCIE2_AXI_S_BRIDGE_CLK>,
					<&gcc GCC_PCIE2_AXI_S_CLK>,
					<&gcc GCC_PCIE2_RCHNG_CLK>;

			assigned-clock-rates = <20000000>,
						<266666666>,
						<240000000>,
						<240000000>,
						<100000000>;

			resets = <&gcc GCC_PCIE2_PIPE_ARES>,
				 <&gcc GCC_PCIE2_CORE_STICKY_RESET>,
				 <&gcc GCC_PCIE2_AXI_M_ARES>,
				 <&gcc GCC_PCIE2_AXI_S_ARES>,
				 <&gcc GCC_PCIE2_AXI_M_STICKY_RESET>,
				 <&gcc GCC_PCIE2_AXI_S_STICKY_RESET>,
				 <&gcc GCC_PCIE2_AHB_ARES>,
				 <&gcc GCC_PCIE2_AUX_ARES>;

			reset-names = "pipe",
				      "sticky",
				      "axi_m",
				      "axi_s",
				      "axi_m_sticky",
				      "axi_s_sticky",
				      "ahb",
				      "aux";

			msi-parent = <&intc>;

			pinctrl-0 = <&pcie2_default_state>;
			pinctrl-names = "default";

			phys = <&pcie2_lanes>;
			phy-names = "pciephy";

			perst-gpio = <&tlmm 41 GPIO_ACTIVE_LOW>;
			status = "disabled";
		};

		/* 1L controller */
		pcie1: pcie@60000000 {
			compatible = "qcom,pcie-devsoc";
			reg =  <0x60000000 0xf1d>,
			       <0x60000f20 0xa8>,
			       <0x60001000 0x1000>,
			       <0x88000 0x3000>,
			       <0x60100000 0x1000>;
			reg-names = "dbi", "elbi", "atu", "parf", "config";
			device_type = "pci";
			linux,pci-domain = <1>;
			bus-range = <0x00 0xff>;
			num-lanes = <1>;
			#address-cells = <3>;
			#size-cells = <2>;

			ranges = <0x81000000 0 0x60200000 0x60200000 0 0x00100000>,   /* downstream I/O */
				 <0x82000000 0 0x60300000 0x60300000 0 0x0fd00000>; /* non-prefetchable memory */

			#interrupt-cells = <1>;
			interrupt-map-mask = <0 0 0 0x7>;
			interrupt-map = <0 0 0 1 &intc 0 449 IRQ_TYPE_LEVEL_HIGH>, /* int_a */
					<0 0 0 2 &intc 0 450 IRQ_TYPE_LEVEL_HIGH>, /* int_b */
					<0 0 0 3 &intc 0 451 IRQ_TYPE_LEVEL_HIGH>, /* int_c */
					<0 0 0 4 &intc 0 452 IRQ_TYPE_LEVEL_HIGH>; /* int_d */

			interrupts = <GIC_SPI 448 IRQ_TYPE_LEVEL_HIGH>;
			interrupt-names = "global_irq";

			clocks = <&gcc GCC_PCIE1_AXI_M_CLK>,
				 <&gcc GCC_PCIE1_AXI_S_CLK>,
				 <&gcc GCC_PCIE1_AHB_CLK>,
				 <&gcc GCC_PCIE1_AUX_CLK>,
				 <&gcc GCC_PCIE1_AXI_S_BRIDGE_CLK>,
				 <&gcc GCC_PCIE1_RCHNG_CLK>;

			clock-names = "axi_m",
				      "axi_s",
				      "ahb",
				      "aux",
				      "axi_bridge",
				      "rchng";

			assigned-clocks = <&gcc GCC_PCIE1_AUX_CLK>,
					<&gcc GCC_PCIE1_AXI_M_CLK>,
					<&gcc GCC_PCIE1_AXI_S_BRIDGE_CLK>,
					<&gcc GCC_PCIE1_AXI_S_CLK>,
					<&gcc GCC_PCIE1_RCHNG_CLK>;

			assigned-clock-rates = <20000000>,
						<240000000>,
						<240000000>,
						<240000000>,
						<100000000>;

			resets = <&gcc GCC_PCIE1_PIPE_ARES>,
				 <&gcc GCC_PCIE1_CORE_STICKY_RESET>,
				 <&gcc GCC_PCIE1_AXI_M_ARES>,
				 <&gcc GCC_PCIE1_AXI_S_ARES>,
				 <&gcc GCC_PCIE1_AXI_M_STICKY_RESET>,
				 <&gcc GCC_PCIE1_AXI_S_STICKY_RESET>,
				 <&gcc GCC_PCIE1_AHB_ARES>,
				 <&gcc GCC_PCIE1_AUX_ARES>;

			reset-names = "pipe",
				      "sticky",
				      "axi_m",
				      "axi_s",
				      "axi_m_sticky",
				      "axi_s_sticky",
				      "ahb",
				      "aux";

			msi-parent = <&intc>;

			pinctrl-0 = <&pcie1_default_state>;
			pinctrl-names = "default";

			phys = <&pcie1_lanes>;
			phy-names = "pciephy";

			perst-gpio = <&tlmm 40 GPIO_ACTIVE_LOW>;
			status = "disabled";
		};

		/* 1L controller */
		pcie0: pcie@70000000 {
			compatible = "qcom,pcie-devsoc";
			reg =  <0x70000000 0xf1d>,
			       <0x70000f20 0xa8>,
			       <0x70001000 0x1000>,
			       <0x80000 0x3000>,
			       <0x70100000 0x1000>;
			reg-names = "dbi", "elbi", "atu", "parf", "config";
			device_type = "pci";
			linux,pci-domain = <0>;
			bus-range = <0x00 0xff>;
			num-lanes = <1>;
			#address-cells = <3>;
			#size-cells = <2>;

			ranges = <0x81000000 0 0x70200000 0x70200000 0 0x00100000>,   /* downstream I/O */
				 <0x82000000 0 0x70300000 0x70300000 0 0x0fd00000>; /* non-prefetchable memory */

			#interrupt-cells = <1>;
			interrupt-map-mask = <0 0 0 0x7>;
			interrupt-map = <0 0 0 1 &intc 0 434 IRQ_TYPE_LEVEL_HIGH>, /* int_a */
					<0 0 0 2 &intc 0 435 IRQ_TYPE_LEVEL_HIGH>, /* int_b */
					<0 0 0 3 &intc 0 436 IRQ_TYPE_LEVEL_HIGH>, /* int_c */
					<0 0 0 4 &intc 0 437 IRQ_TYPE_LEVEL_HIGH>; /* int_d */

			interrupts = <GIC_SPI 433 IRQ_TYPE_LEVEL_HIGH>;
			interrupt-names = "global_irq";

			clocks = <&gcc GCC_PCIE0_AXI_M_CLK>,
				 <&gcc GCC_PCIE0_AXI_S_CLK>,
				 <&gcc GCC_PCIE0_AHB_CLK>,
				 <&gcc GCC_PCIE0_AUX_CLK>,
				 <&gcc GCC_PCIE0_AXI_S_BRIDGE_CLK>,
				 <&gcc GCC_PCIE0_RCHNG_CLK>;

			clock-names = "axi_m",
				      "axi_s",
				      "ahb",
				      "aux",
				      "axi_bridge",
				      "rchng";

			assigned-clocks = <&gcc GCC_PCIE0_AUX_CLK>,
					<&gcc GCC_PCIE0_AXI_M_CLK>,
					<&gcc GCC_PCIE0_AXI_S_BRIDGE_CLK>,
					<&gcc GCC_PCIE0_AXI_S_CLK>,
					<&gcc GCC_PCIE0_RCHNG_CLK>;

			assigned-clock-rates = <2000000>,
						<240000000>,
						<240000000>,
						<240000000>,
						<100000000>;

			resets = <&gcc GCC_PCIE0_PIPE_ARES>,
				 <&gcc GCC_PCIE0_CORE_STICKY_RESET>,
				 <&gcc GCC_PCIE0_AXI_M_ARES>,
				 <&gcc GCC_PCIE0_AXI_S_ARES>,
				 <&gcc GCC_PCIE0_AXI_M_STICKY_RESET>,
				 <&gcc GCC_PCIE0_AXI_S_STICKY_RESET>,
				 <&gcc GCC_PCIE0_AHB_ARES>,
				 <&gcc GCC_PCIE0_AUX_ARES>;

			reset-names = "pipe",
				      "sticky",
				      "axi_m",
				      "axi_s",
				      "axi_m_sticky",
				      "axi_s_sticky",
				      "ahb",
				      "aux";

			msi-parent = <&intc>;

			pinctrl-0 = <&pcie0_default_state>;
			pinctrl-names = "default";

			phys = <&pcie0_lanes>;
			phy-names = "pciephy";

			perst-gpio = <&tlmm 39 GPIO_ACTIVE_LOW>;
			status = "disabled";
		};
	};

	timer {
		compatible = "arm,armv8-timer";
		interrupts = <GIC_PPI 13 (GIC_CPU_MASK_SIMPLE(4) | IRQ_TYPE_LEVEL_LOW)>,
			     <GIC_PPI 14 (GIC_CPU_MASK_SIMPLE(4) | IRQ_TYPE_LEVEL_LOW)>,
			     <GIC_PPI 11 (GIC_CPU_MASK_SIMPLE(4) | IRQ_TYPE_LEVEL_LOW)>,
			     <GIC_PPI 10 (GIC_CPU_MASK_SIMPLE(4) | IRQ_TYPE_LEVEL_LOW)>,
			     <GIC_PPI 12 (GIC_CPU_MASK_SIMPLE(4) | IRQ_TYPE_LEVEL_LOW)>;
	};

	qcom,test@0 {
		compatible = "qcom,testmhi";
		qcom,wlan-ramdump-dynamic = <0x600000>;
	};

	wcss: wcss-smp2p {
		compatible = "qcom,smp2p";
		qcom,smem = <435>, <428>;

		interrupt-parent = <&intc>;
		interrupts = <GIC_SPI 501 IRQ_TYPE_EDGE_RISING>;

		mboxes = <&apcs_glb 9>;

		qcom,local-pid = <0>;
		qcom,remote-pid = <1>;

		wcss_smp2p_out: master-kernel {
			qcom,entry-name = "master-kernel";
			#qcom,smem-state-cells = <1>;
		};

		wcss_smp2p_in: slave-kernel {
			qcom,entry-name = "slave-kernel";
			interrupt-controller;
			#interrupt-cells = <2>;
		};
	};
};
